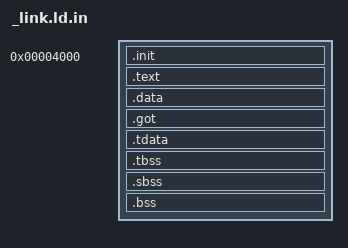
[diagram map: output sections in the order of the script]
STARTUP(../libc/arch/ARCH/src/entry.o)
ENTRY(__start)

PHDRS {
	text PT_LOAD FLAGS(5);
	data PT_LOAD FLAGS(6);
}

SECTIONS {
	. = 0x4000;
	
	.init ALIGN(0x4000) : SUBALIGN(0x4000) {
		*(.init);
	} :text
	.text : {
	        *(.text);
		*(.rodata*);
	} :text

	.data : {
		*(.data);
		*(.data.rel*);
	} :data

	.got : {
		_gp = .;
		*(.got);
	} :data

	.tdata : {
		_tdata_start = .;
		*(.tdata);
		_tdata_end = .;
	} :data
	.tbss : {
		_tbss_start = .;
		*(.tbss);
		_tbss_end = .;
	} :data

	.sbss : {
		*(.scommon);
		*(.sbss);
	}	
	.bss : {
		*(.bss);
		*(COMMON);
		_heap = .;
		LONG(0xdeadbeef);
	} :data

	/DISCARD/ : {
		*(*);
	}
}
